# RZT2L register map
Vendor: Renesas Electronics Corporation; Series: RZT; File version: 1.20.00
CPU: other r0p0, little endian, MPU, no FPU, VTOR, 4 interrupt priority bits, 624 interrupts
Registers are 32-bit, read-write, reset 0x0 unless marked. A register's access mark holds for its fields unless they carry their own. Offsets are from the block's base; [hi:lo] are bit positions; 'fields as' and 'values as' point back to an identical list.

## MTU_NF — Multi-Function Timer Pulse Unit Noise Filter
Base 0x90001290
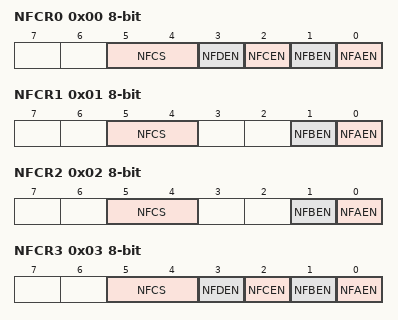
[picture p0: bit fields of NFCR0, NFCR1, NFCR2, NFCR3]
0x00 NFCR0 8-bit — Noise Filter Control Register 0
  [5:4] NFCS — Noise Filter Clock Select
    0=PCLKH/1; 1=PCLKH/8; 2=PCLKH/32; 3=Clock source for counting
  [3] NFDEN — Noise Filter D Enable
    0=The noise filter for the MTIOCnD pin is disabled; 1=The noise filter for the MTIOCnD pin is enabled
  [2] NFCEN — Noise Filter C Enable
    0=The noise filter for the MTIOCnC pin is disabled; 1=The noise filter for the MTIOCnC pin is enabled
  [1] NFBEN — Noise Filter B Enable
    0=The noise filter for the MTIOCnB pin is disabled; 1=The noise filter for the MTIOCnB pin is enabled
  [0] NFAEN — Noise Filter A Enable
    0=The noise filter for the MTIOCnA pin is disabled; 1=The noise filter for the MTIOCnA pin is enabled
0x01 NFCR1 8-bit — Noise Filter Control Register 1
  [5:4] NFCS — Noise Filter Clock Select
    values as NFCR0.NFCS
  [1] NFBEN — Noise Filter B Enable
    0=The noise filter for the MTIOCmB pin is disabled; 1=The noise filter for the MTIOCmB pin is enabled
  [0] NFAEN — Noise Filter A Enable
    0=The noise filter for the MTIOCmA pin is disabled; 1=The noise filter for the MTIOCmA pin is enabled
0x02 NFCR2 8-bit — Noise Filter Control Register 2
  fields as NFCR1
0x03 NFCR3 8-bit — Noise Filter Control Register 3
  fields as NFCR0
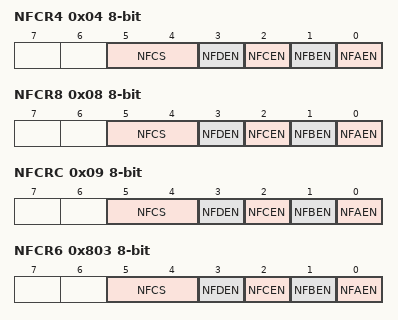
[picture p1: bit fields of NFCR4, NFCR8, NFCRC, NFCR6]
0x04 NFCR4 8-bit — Noise Filter Control Register 4
  fields as NFCR0
0x08 NFCR8 8-bit — Noise Filter Control Register 8
  fields as NFCR0
0x09 NFCRC 8-bit — Noise Filter Control Register C
  [5:4] NFCS — Noise Filter Clock Select
    0=PCLKH/1; 1=PCLKH/2; 2=PCLKH/8; 3=PCLKH/32
  [3] NFDEN — Noise Filter D Enable
    0=The noise filter for the MTCLKD pin is disabled; 1=The noise filter for the MTCLKD pin is enabled
  [2] NFCEN — Noise Filter C Enable
    0=The noise filter for the MTCLKC pin is disabled; 1=The noise filter for the MTCLKC pin is enabled
  [1] NFBEN — Noise Filter B Enable
    0=The noise filter for the MTCLKB pin is disabled; 1=The noise filter for the MTCLKB pin is enabled
  [0] NFAEN — Noise Filter A Enable
    0=The noise filter for the MTCLKA pin is disabled; 1=The noise filter for the MTCLKA pin is enabled
0x803 NFCR6 8-bit — Noise Filter Control Register 6
  fields as NFCR0
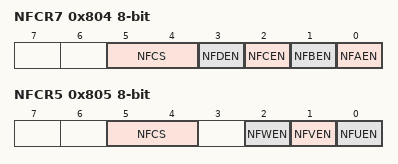
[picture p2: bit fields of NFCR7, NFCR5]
0x804 NFCR7 8-bit — Noise Filter Control Register 7
  fields as NFCR0
0x805 NFCR5 8-bit — Noise Filter Control Register 5
  [5:4] NFCS — Noise Filter Clock Select
    values as NFCR0.NFCS
  [2] NFWEN — Noise Filter W Enable
    0=The noise filter for the MTIC5W pin is disabled; 1=The noise filter for the MTIC5W pin is enabled
  [1] NFVEN — Noise Filter V Enable
    0=The noise filter for the MTIC5V pin is disabled; 1=The noise filter for the MTIC5V pin is enabled
  [0] NFUEN — Noise Filter U Enable
    0=The noise filter for the MTIC5U pin is disabled; 1=The noise filter for the MTIC5U pin is enabled

## MTU0 — Multi-Function Timer Pulse Unit Channel 0
Base 0x90001300
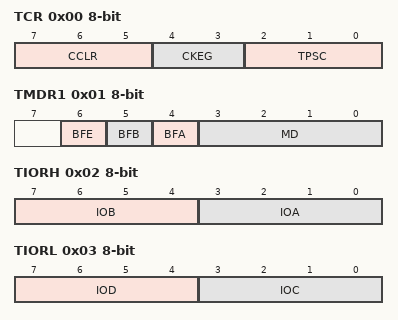
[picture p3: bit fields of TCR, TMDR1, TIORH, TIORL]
0x00 TCR 8-bit — Timer Control Register
  [7:5] CCLR — Counter Clear Source Select
  [4:3] CKEG — Clock Edge Select
    0=Count at rising edge; 1=Count at falling edge; 0b1x=Count at both edges
  [2:0] TPSC — Time Prescaler Select
0x01 TMDR1 8-bit — Timer Mode Register 1
  [6] BFE — Buffer Operation E
    0=MTU0.TGRE and MTU0.TGRF operate normally; 1=MTU0.TGRE and MTU0.TGRF used together for buffer operation
  [5] BFB — Buffer Operation B
    0=TGRB and TGRD operate normally; 1=TGRB and TGRD used together for buffer operation
  [4] BFA — Buffer Operation A
    0=TGRA and TGRC operate normally; 1=TGRA and TGRC used together for buffer operation
  [3:0] MD — Mode Select
0x02 TIORH 8-bit — Timer I/O Control Register H
  [7:4] IOB — I/O Control B
  [3:0] IOA — I/O Control A
0x03 TIORL 8-bit — Timer I/O Control Register L
  [7:4] IOD — I/O Control B
  [3:0] IOC — I/O Control A
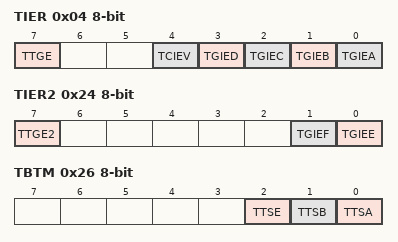
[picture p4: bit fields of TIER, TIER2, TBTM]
0x04 TIER 8-bit — Timer Interrupt Enable Register
  [7] TTGE — A/D Converter Start Request Enable
    0=A/D converter start request generation disabled; 1=A/D converter start request generation enabled
  [4] TCIEV — Overflow Interrupt Enable
    0=Interrupt requests (TCIV) disabled; 1=Interrupt requests (TCIV) enabled
  [3] TGIED — TGR Interrupt Enable D
    0=Interrupt requests (TGID) disabled; 1=Interrupt requests (TGID) enabled
  [2] TGIEC — TGR Interrupt Enable C
    0=Interrupt requests (TGIC) disabled; 1=Interrupt requests (TGIC) enabled
  [1] TGIEB — TGR Interrupt Enable B
    0=Interrupt requests (TGIB) disabled; 1=Interrupt requests (TGIB) enabled
  [0] TGIEA — TGR Interrupt Enable A
    0=Interrupt requests (TGIA) disabled; 1=Interrupt requests (TGIA) enabled
0x06 TCNT 16-bit — Timer Counter
0x08 TGRA 16-bit reset 0xFFFF — Timer General Register A
0x0A TGRB 16-bit reset 0xFFFF — Timer General Register B
0x0C TGRC 16-bit reset 0xFFFF — Timer General Register C
0x0E TGRD 16-bit reset 0xFFFF — Timer General Register D
0x20 TGRE 16-bit reset 0xFFFF — Timer General Register E
0x22 TGRF 16-bit reset 0xFFFF — Timer General Register F
0x24 TIER2 8-bit — Timer Interrupt Enable Register 2
  [7] TTGE2 — A/D Converter Start Request Enable 2
    0=A/D converter start request generation by compare match between MTU0.TCNT and MTU0.TGRE disabled; 1=A/D converter start request generation by compare match between MTU0.TCNT and MTU0.TGRE enabled
  [1] TGIEF — TGR Interrupt Enable F
    0=Interrupt requests (TGIF) disabled; 1=Interrupt requests (TGIF) enabled
  [0] TGIEE — TGR Interrupt Enable E
    0=Interrupt requests (TGIE) disabled; 1=Interrupt requests (TGIE) enabled
0x26 TBTM 8-bit — Timer Buffer Operation Transfer Mode Register
  [2] TTSE — Timing Select E
    0=When compare match E occurs in MTU0, data is transferred from MTU0.TGRF to MTU0.TGRE; 1=When MTU0.TCNT is cleared in MTU0, data is transferred from MTU0.TGRF to MTU0.TGRE
  [1] TTSB — Timing Select B
    0=When compare match B occurs in each channel, data is transferred from TGRD to TGRB; 1=When TCNT is cleared in each channel, data is transferred from TGRD to TGRB
  [0] TTSA — Timing Select A
    0=When compare match A occurs in each channel, data is transferred from TGRC to TGRA; 1=When TCNT is cleared in each channel, data is transferred from TGRC to TGRA
0x28 TCR2 8-bit — Timer Control Register 2
  [2:0] TPSC2 — Time Prescaler Select
